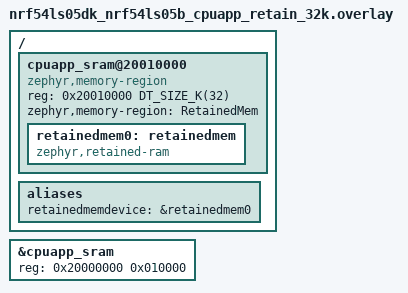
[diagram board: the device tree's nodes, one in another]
/ {
	cpuapp_sram@20010000 {
		compatible = "zephyr,memory-region", "mmio-sram";
		reg = <0x20010000 DT_SIZE_K(32)>;
		zephyr,memory-region = "RetainedMem";
		status = "okay";

		retainedmem0: retainedmem {
			compatible = "zephyr,retained-ram";
			status = "okay";
		};
	};

	aliases {
		retainedmemdevice = &retainedmem0;
	};
};

&cpuapp_sram {
	/* Shrink SRAM size to avoid overlap with retained memory region:
	 * 96 - 32 = 64KB = 0x10000
	 */
	reg = <0x20000000 0x010000>;
	ranges = <0x0 0x20000000 0x010000>;
};
